VERSION "AutoDiag application protocol v1"

NS_ :

BS_:

BU_: BMS HVAC Body Monitor

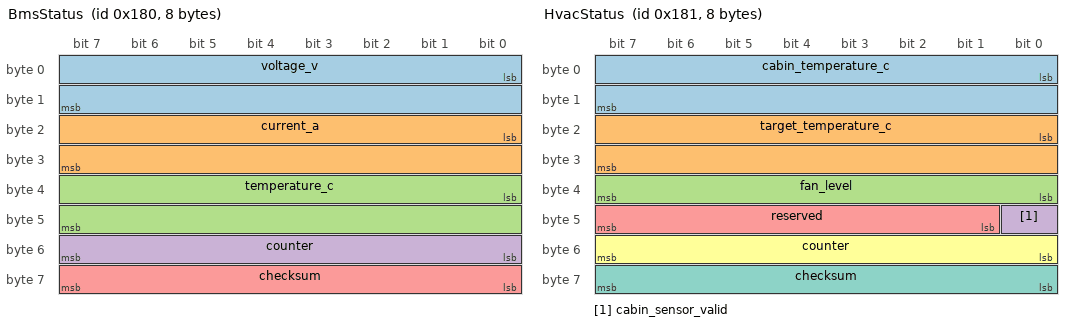
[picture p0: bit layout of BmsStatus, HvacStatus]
BO_ 384 BmsStatus: 8 BMS
 SG_ voltage_v : 0|16@1+ (0.1,0) [0|800] "V" Monitor
 SG_ current_a : 16|16@1- (0.1,0) [-200|200] "A" Monitor
 SG_ temperature_c : 32|16@1- (0.1,0) [-40|150] "degC" Monitor
 SG_ counter : 48|8@1+ (1,0) [0|255] "" Monitor
 SG_ checksum : 56|8@1+ (1,0) [0|255] "" Monitor

BO_ 385 HvacStatus: 8 HVAC
 SG_ cabin_temperature_c : 0|16@1- (0.1,0) [-40|125] "degC" Monitor
 SG_ target_temperature_c : 16|16@1- (0.1,0) [16|32] "degC" Monitor
 SG_ fan_level : 32|8@1+ (1,0) [0|7] "" Monitor
 SG_ cabin_sensor_valid : 40|1@1+ (1,0) [0|1] "" Monitor
 SG_ reserved : 41|7@1+ (1,0) [0|0] "" Monitor
 SG_ counter : 48|8@1+ (1,0) [0|255] "" Monitor
 SG_ checksum : 56|8@1+ (1,0) [0|255] "" Monitor

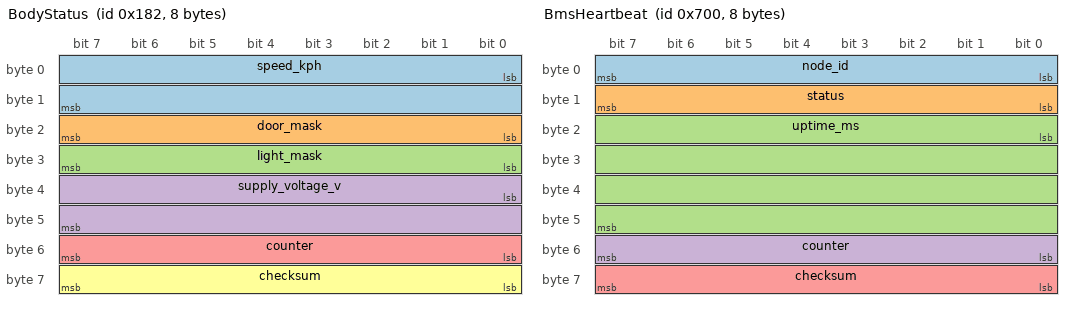
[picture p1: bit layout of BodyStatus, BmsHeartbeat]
BO_ 386 BodyStatus: 8 Body
 SG_ speed_kph : 0|16@1+ (0.01,0) [0|200] "km/h" Monitor
 SG_ door_mask : 16|8@1+ (1,0) [0|31] "" Monitor
 SG_ light_mask : 24|8@1+ (1,0) [0|7] "" Monitor
 SG_ supply_voltage_v : 32|16@1+ (0.01,0) [0|25] "V" Monitor
 SG_ counter : 48|8@1+ (1,0) [0|255] "" Monitor
 SG_ checksum : 56|8@1+ (1,0) [0|255] "" Monitor

BO_ 1792 BmsHeartbeat: 8 BMS
 SG_ node_id : 0|8@1+ (1,0) [1|1] "" Monitor
 SG_ status : 8|8@1+ (1,0) [1|1] "" Monitor
 SG_ uptime_ms : 16|32@1+ (1,0) [0|4294967295] "ms" Monitor
 SG_ counter : 48|8@1+ (1,0) [0|255] "" Monitor
 SG_ checksum : 56|8@1+ (1,0) [0|255] "" Monitor

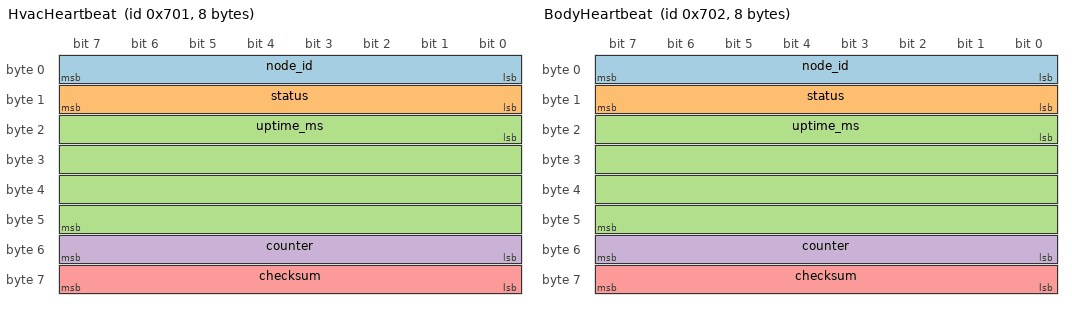
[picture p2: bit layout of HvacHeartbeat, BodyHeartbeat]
BO_ 1793 HvacHeartbeat: 8 HVAC
 SG_ node_id : 0|8@1+ (1,0) [2|2] "" Monitor
 SG_ status : 8|8@1+ (1,0) [1|5] "" Monitor
 SG_ uptime_ms : 16|32@1+ (1,0) [0|4294967295] "ms" Monitor
 SG_ counter : 48|8@1+ (1,0) [0|255] "" Monitor
 SG_ checksum : 56|8@1+ (1,0) [0|255] "" Monitor

BO_ 1794 BodyHeartbeat: 8 Body
 SG_ node_id : 0|8@1+ (1,0) [3|3] "" Monitor
 SG_ status : 8|8@1+ (1,0) [1|1] "" Monitor
 SG_ uptime_ms : 16|32@1+ (1,0) [0|4294967295] "ms" Monitor
 SG_ counter : 48|8@1+ (1,0) [0|255] "" Monitor
 SG_ checksum : 56|8@1+ (1,0) [0|255] "" Monitor

CM_ "Pure software application protocol. A checksum signal is not automatically validated by DBC tools.";
CM_ SG_ 385 reserved "Must be zero. Cabin temperature is last-good when cabin_sensor_valid=0.";
CM_ SG_ 1793 status "Only 1 (running) and 5 (running + degraded LIN input) are valid; numeric min/max alone is insufficient.";
BA_DEF_ BO_ "GenMsgCycleTime" INT 0 65535;
BA_DEF_DEF_ "GenMsgCycleTime" 0;
BA_ "GenMsgCycleTime" BO_ 384 100;
BA_ "GenMsgCycleTime" BO_ 385 100;
BA_ "GenMsgCycleTime" BO_ 386 100;
BA_ "GenMsgCycleTime" BO_ 1792 250;
BA_ "GenMsgCycleTime" BO_ 1793 250;
BA_ "GenMsgCycleTime" BO_ 1794 250;
